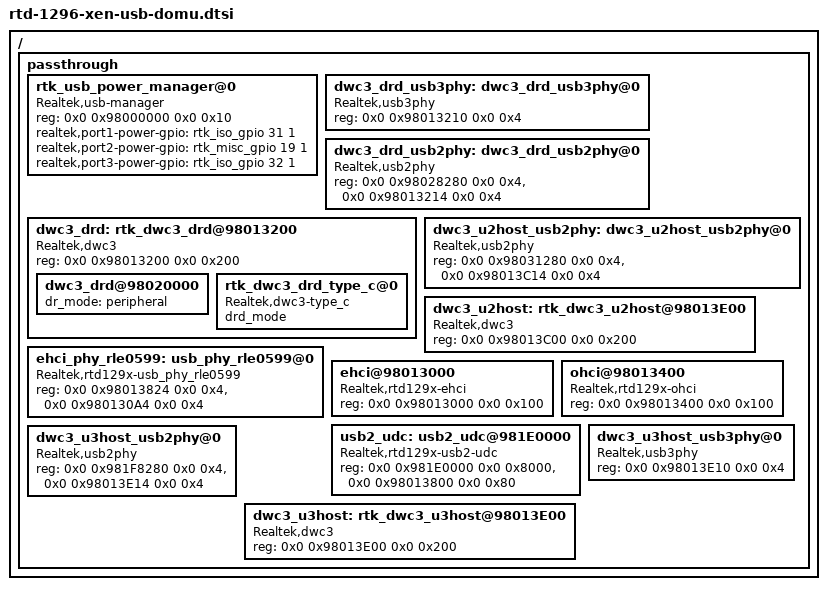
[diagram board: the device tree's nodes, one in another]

/ {
	passthrough {

	/include/ "rtd-129x-usb.dtsi"

	rtk_usb_power_manager@0 {
		compatible = "Realtek,usb-manager";
		reg = <0x0 0x98000000 0x0 0x10>;
		realtek,port1-power-gpio = <&rtk_iso_gpio 31 1 0>; /*u2host power, output, default low */
		realtek,port2-power-gpio = <&rtk_misc_gpio 19 1 0>; /*ehci power, output, default low */
		realtek,port3-power-gpio = <&rtk_iso_gpio 32 1 0>; /*1296 u3host power, output, default low */

		status = "okay";
	};

	dwc3_drd_usb3phy: dwc3_drd_usb3phy@0 {
		compatible = "Realtek,usb3phy";
		reg = <0x0 0x98013210 0x0 0x4>;
		ranges = <0x98000000 0x0 0x98000000 0x200000>;
	};

	dwc3_drd_usb2phy: dwc3_drd_usb2phy@0 {
		compatible = "Realtek,usb2phy";
		reg = <0x0 0x98028280 0x0 0x4>,
		      <0x0 0x98013214 0x0 0x4>;
		ranges = <0x98000000 0x0 0x98000000 0x200000>;
	};

	dwc3_drd: rtk_dwc3_drd@98013200 {
		compatible = "Realtek,dwc3";
		reg = <0x0 0x98013200 0x0 0x200>;
		status = "okay";
		ranges = <0x98000000 0x0 0x98000000 0x200000>;

		dwc3_drd@98020000 {
			dr_mode = "peripheral"; /*host, peripheral*/
		};

		rtk_dwc3_drd_type_c@0 {
			compatible = "Realtek,dwc3-type_c";
			drd_mode;  //depend on dr_mode = "peripheral"
		};

	};

	dwc3_u2host_usb2phy: dwc3_u2host_usb2phy@0 {
		compatible = "Realtek,usb2phy";
		reg = <0x0 0x98031280 0x0 0x4>,
		      <0x0 0x98013C14 0x0 0x4>;
		ranges = <0x98000000 0x0 0x98000000 0x200000>;
	};

	dwc3_u2host: rtk_dwc3_u2host@98013E00 {
		compatible = "Realtek,dwc3";
		reg = <0x0 0x98013C00 0x0 0x200>;
		status = "okay";
		ranges = <0x98000000 0x0 0x98000000 0x200000>;
	};

	ehci_phy_rle0599: usb_phy_rle0599@0 {
		compatible = "Realtek,rtd129x-usb_phy_rle0599";
		reg = <0x0 0x98013824 0x0 0x4>,
		      <0x0 0x980130A4 0x0 0x4>;
	};

	ehci@98013000 {
		compatible = "Realtek,rtd129x-ehci";
		reg = <0x0 0x98013000 0x0 0x100>;
		status = "okay";
	};

	ohci@98013400 {
		compatible = "Realtek,rtd129x-ohci";
		reg = <0x0 0x98013400 0x0 0x100>;
		status = "okay";
	};

	usb2_udc: usb2_udc@981E0000 {
		compatible = "Realtek,rtd129x-usb2-udc";
		reg = <0x0 0x981E0000 0x0 0x8000>,
		      <0x0 0x98013800 0x0 0x80>;
	};

	dwc3_u3host_usb3phy@0 {
		compatible = "Realtek,usb3phy";
		reg = <0x0 0x98013E10 0x0 0x4>;
		status = "okay";
		ranges = <0x98000000 0x0 0x98000000 0x200000>;
	};

	dwc3_u3host_usb2phy@0 {
		compatible = "Realtek,usb2phy";
		reg = <0x0 0x981F8280 0x0 0x4>,
		      <0x0 0x98013E14 0x0 0x4>;
		status = "okay";
		ranges = <0x98000000 0x0 0x98000000 0x200000>;
	};

	dwc3_u3host: rtk_dwc3_u3host@98013E00 {
		compatible = "Realtek,dwc3";
		reg = <0x0 0x98013E00 0x0 0x200>;
		status = "okay";
		ranges = <0x98000000 0x0 0x98000000 0x200000>;
	};

	}; /* passthrough */
};
